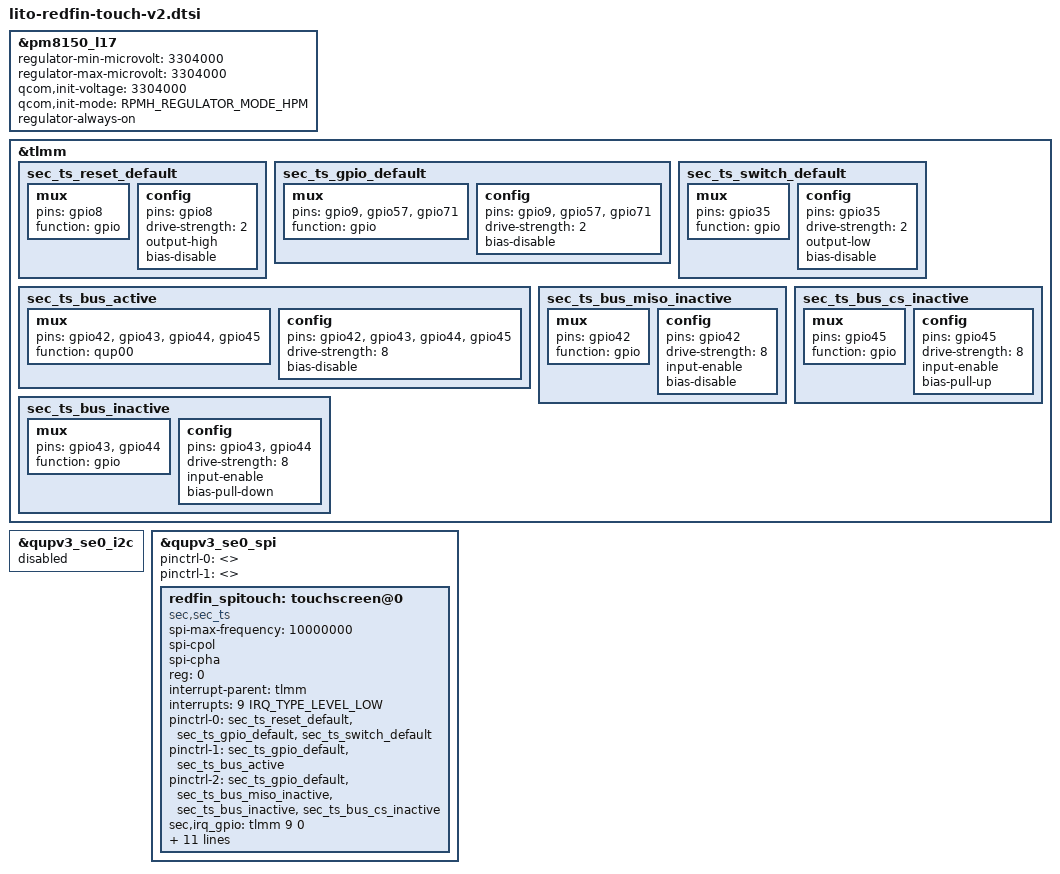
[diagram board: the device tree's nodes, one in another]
// SPDX-License-Identifier: GPL-2.0
/* Copyright (c) 2020, The Linux Foundation. All rights reserved.
 *
 * This program is free software; you can redistribute it and/or modify
 * it under the terms of the GNU General Public License version 2 and
 * only version 2 as published by the Free Software Foundation.
 *
 * This program is distributed in the hope that it will be useful,
 * but WITHOUT ANY WARRANTY; without even the implied warranty of
 * MERCHANTABILITY or FITNESS FOR A PARTICULAR PURPOSE.  See the
 * GNU General Public License for more details.
 */
#include <dt-bindings/regulator/qcom,rpmh-regulator-levels.h>

/* AP Touch SPI MISO is gpio42, MOSI is gpio43, CLK is gpio44, CS is gpio45.
 * Reset - gpio8
 * Interrupt - gpio9
 * Bus master switch - gpio35
 * LPI2AP - gpio57
 * AP2LPI - gpio71
 */

&pm8150_l17 {
	regulator-min-microvolt = <3304000>;
	regulator-max-microvolt = <3304000>;
	qcom,init-voltage = <3304000>;
	qcom,init-mode = <RPMH_REGULATOR_MODE_HPM>;
	regulator-always-on;
};

&tlmm {
	sec_ts_reset_default: sec_ts_reset_default {
		mux {
			pins = "gpio8";
			function = "gpio";
		};

		config {
			pins = "gpio8";
			drive-strength = <2>;
			output-high;
			bias-disable;
		};
	};

	sec_ts_gpio_default: sec_ts_gpio_default {
		mux {
			pins = "gpio9", "gpio57", "gpio71";
			function = "gpio";
		};

		config {
			pins = "gpio9", "gpio57", "gpio71";
			drive-strength = <2>;
			bias-disable;
		};
	};

	sec_ts_switch_default: sec_ts_switch_default {
		mux {
			pins = "gpio35";
			function = "gpio";
		};

		config {
			pins = "gpio35";
			drive-strength = <2>;
			output-low;
			bias-disable;
		};
	};

	/* bus active: MISO, MOSI, CLK and CS */
	sec_ts_bus_active: sec_ts_bus_active {
		mux {
			pins = "gpio42", "gpio43", "gpio44", "gpio45";
			function = "qup00";
		};

		config {
			pins = "gpio42", "gpio43", "gpio44", "gpio45";
			drive-strength = <8>;
			bias-disable;
		};
	};

	/* bus inactive: MISO */
	sec_ts_bus_miso_inactive: sec_ts_bus_miso_inactive {
		mux {
			pins = "gpio42";
			function = "gpio";
		};

		config {
			pins = "gpio42";
			drive-strength = <8>;
			input-enable;
			bias-disable;
		};
	};

	/* bus inactive: MOSI, CLK */
	sec_ts_bus_inactive: sec_ts_bus_inactive {
		mux {
			pins = "gpio43", "gpio44";
			function = "gpio";
		};

		config {
			pins = "gpio43", "gpio44";
			drive-strength = <8>;
			input-enable;
			bias-pull-down;
		};
	};

	/* bus inactive: CS */
	sec_ts_bus_cs_inactive: sec_ts_bus_cs_inactive {
		mux {
			pins = "gpio45";
			function = "gpio";
		};

		config {
			pins = "gpio45";
			drive-strength = <8>;
			input-enable;
			bias-pull-up;
		};
	};
};

&qupv3_se0_i2c {
	status = "disabled";
};

&qupv3_se0_spi {
	status = "ok";
	pinctrl-0 = <>;
	pinctrl-1 = <>;

	redfin_spitouch: touchscreen@0 {
		status = "ok";
		compatible = "sec,sec_ts";
		spi-max-frequency = <10000000>;
		spi-cpol;
		spi-cpha;

		reg = <0>;
		interrupt-parent = <&tlmm>;
		interrupts = <9 IRQ_TYPE_LEVEL_LOW>;

		pinctrl-names = "default", "on_state", "off_state";
		pinctrl-0 = <&sec_ts_reset_default
				&sec_ts_gpio_default
				&sec_ts_switch_default>;
		pinctrl-1 = <&sec_ts_gpio_default
				&sec_ts_bus_active>;
		pinctrl-2 = <&sec_ts_gpio_default
				&sec_ts_bus_miso_inactive
				&sec_ts_bus_inactive
				&sec_ts_bus_cs_inactive>;

		sec,irq_gpio = <&tlmm 9 0>;
		sec,reset_gpio = <&tlmm 8 0>;
		sec,firmware_name = "s6sy79x.bin";
		sec,mis_cal_check = <1>;
		sec,heatmap_mode = <1>;

		sec,max_coords = <1080 2340>;

		avdd-supply = <&pm8150_l17>;
		sec,regulator_avdd = "avdd";
		sec,panel_map = <&dsi_s6e3hc2_dsc_1080p_cmd 0>,
				<&dsi_s6e3hc2_evt_dsc_1080p_cmd 0>;
		tbn,lpi2ap_gpio = <&tlmm 57 0>;
		tbn,ap2lpi_gpio = <&tlmm 71 0>;

	};
};
